# STM32F091x register map
File version: 1.0
CPU: 
Registers are 32-bit, read-write, reset 0x0 unless marked. A register's access mark holds for its fields unless they carry their own. Offsets are from the block's base; lines under a group give offsets from that group; [hi:lo] are bit positions; {n}, {i} and the like mark numbered series; 'fields as' and 'values as' point back to an identical list; <NAME> marks a mode.

## Memory map
0x40000000 TIM2 size 0x400 — General-purpose-timers
0x40000400 TIM3 size 0x400 — General-purpose-timers
0x40001000 TIM6 size 0x400 — Basic-timers
0x40001400 TIM7 size 0x400 — Basic-timers
0x40002000 TIM14 size 0x400 — General-purpose-timers
0x40002800 RTC size 0x400 — Real-time clock
0x40002C00 WWDG size 0x400 — Window watchdog
0x40003000 IWDG size 0x400 — Independent watchdog
0x40003800 SPI2 size 0x400 — Serial peripheral interface
0x40004400 USART2 size 0x400 — Universal synchronous asynchronous receiver transmitter
0x40004800 USART3 size 0x400 — Universal synchronous asynchronous receiver transmitter
0x40004C00 USART4 size 0x400 — Universal synchronous asynchronous receiver transmitter
0x40005400 I2C1 size 0x400 — Inter-integrated circuit
0x40005800 I2C2 size 0x400 — Inter-integrated circuit
0x40005C00 USB size 0x400 — Universal serial bus full-speed device interface
0x40006400 CAN size 0x400 — Controller area network
0x40006C00 CRS size 0x400 — Clock recovery system
0x40007000 PWR size 0x400 — Power control
0x40007400 DAC size 0x400 — Digital-to-analog converter
0x40007800 CEC size 0x400 — HDMI-CEC controller
0x40010000 SYSCFG size 0x400 — System configuration controller
0x4001001C COMP size 0x400 — Comparator
0x40010400 EXTI size 0x400 — External interrupt/event controller
0x40011400 USART6 size 0x400 — Universal synchronous asynchronous receiver transmitter
0x40011800 USART7 size 0x400 — Universal synchronous asynchronous receiver transmitter
0x40011C00 USART8 size 0x400 — Universal synchronous asynchronous receiver transmitter
0x40012400 ADC size 0x400 — Analog-to-digital converter
0x40012C00 TIM1 size 0x400 — Advanced-timers
0x40013000 SPI1 size 0x400 — Serial peripheral interface
0x40013800 USART1 size 0x400 — Universal synchronous asynchronous receiver transmitter
0x40014000 TIM15 size 0x400 — General-purpose-timers
0x40014400 TIM16 size 0x400 — General-purpose-timers
0x40014800 TIM17 size 0x400 — General-purpose-timers
0x40015800 DBGMCU size 0x400 — Debug support
0x40020000 DMA size 0x400 — DMA controller
0x40021000 RCC size 0x400 — Reset and clock control
0x40022000 Flash size 0x400
0x40023000 CRC size 0x400 — cyclic redundancy check calculation unit
0x40024000 TSC size 0x400 — Touch sensing controller
0x48000000 GPIOA size 0x400 — General-purpose I/Os
0x48000400 GPIOB size 0x400 — General-purpose I/Os
0x48000800 GPIOC size 0x400 — General-purpose I/Os
0x48000C00 GPIOD size 0x400 — General-purpose I/Os
0x48001000 GPIOE size 0x400 — General-purpose I/Os
0x48001400 GPIOF size 0x400 — General-purpose I/Os
0xE000E100 NVIC size 0x33D — Nested Vectored Interrupt Controller

## Interrupts
0 WWDG
1 PVD (EXTI)
2 RTC
3 FLASH (Flash)
4 RCC_CRS (RCC, CRS)
5 EXTI0_1 (EXTI)
6 EXTI2_3 (EXTI)
7 EXTI4_15 (EXTI)
8 TSC
9 DMA_CH1 (DMA)
10 DMA_CH2_3 (DMA)
11 DMA_CH4_5_6_7 (DMA)
12 ADC_COMP (ADC, COMP)
13 TIM1_BRK_UP_TRG_COM (TIM1)
14 TIM1_CC (TIM1)
15 TIM2
16 TIM3
17 TIM6_DAC (DAC, TIM6)
18 TIM7
19 TIM14
20 TIM15
21 TIM16
22 TIM17
23 I2C1
24 I2C2
25 SPI1
26 SPI2
27 USART1 (USART1, USART{n} (n=6..8))
28 USART2
29 USART3_4 (USART3, USART4)
30 CEC_CAN (CEC, CAN)
31 USB

## CRC — cyclic redundancy check calculation unit
Base 0x40023000
0x00 DR reset 0xFFFFFFFF — Data register
  [31:0] DR — Data register bits
0x04 IDR — Independent data register
  [7:0] IDR — General-purpose 8-bit data register bits
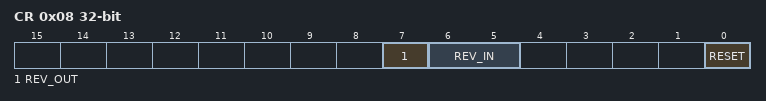
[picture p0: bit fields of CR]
0x08 CR — Control register
  [7] REV_OUT — Reverse output data
  [6:5] REV_IN — Reverse input data
  [0] RESET — reset bit
0x0C INIT reset 0xFFFFFFFF — Initial CRC value
  [31:0] INIT — Programmable initial CRC value
